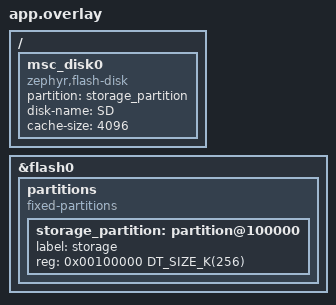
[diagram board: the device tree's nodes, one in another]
/* SPDX-License-Identifier: Apache-2.0 */
/delete-node/ &storage_partition;

&flash0 {
    partitions {
        compatible = "fixed-partitions";
        #address-cells = <1>;
        #size-cells = <1>;

        storage_partition: partition@100000 {
            label = "storage";
            reg = <0x00100000 DT_SIZE_K(256)>;
        };
    };
};

/ {
    msc_disk0 {
        status = "okay";
        compatible = "zephyr,flash-disk";
        partition = <&storage_partition>;
        disk-name = "SD";
        cache-size = <4096>;
    };
};
